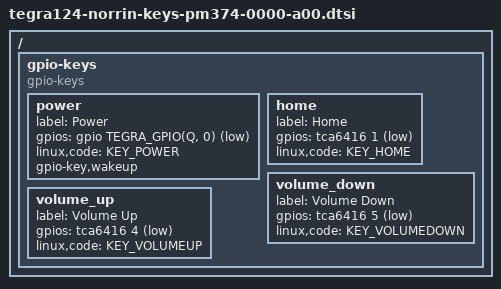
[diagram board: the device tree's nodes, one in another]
#include <dt-bindings/gpio/tegra-gpio.h>
#include <dt-bindings/input/input.h>

/ {
	gpio-keys {
		compatible = "gpio-keys";

		power {
			label = "Power";
			gpios = <&gpio TEGRA_GPIO(Q, 0) GPIO_ACTIVE_LOW>;
			linux,code = <KEY_POWER>;
			gpio-key,wakeup;
		};

		home {
			label = "Home";
			gpios = <&tca6416 1 GPIO_ACTIVE_LOW>;
			linux,code = <KEY_HOME>;
		};

		volume_down {
			label = "Volume Down";
			gpios = <&tca6416 5 GPIO_ACTIVE_LOW>;
			linux,code = <KEY_VOLUMEDOWN>;
		};

		volume_up {
			label = "Volume Up";
			gpios = <&tca6416 4 GPIO_ACTIVE_LOW>;
			linux,code = <KEY_VOLUMEUP>;
		};
	};
};
